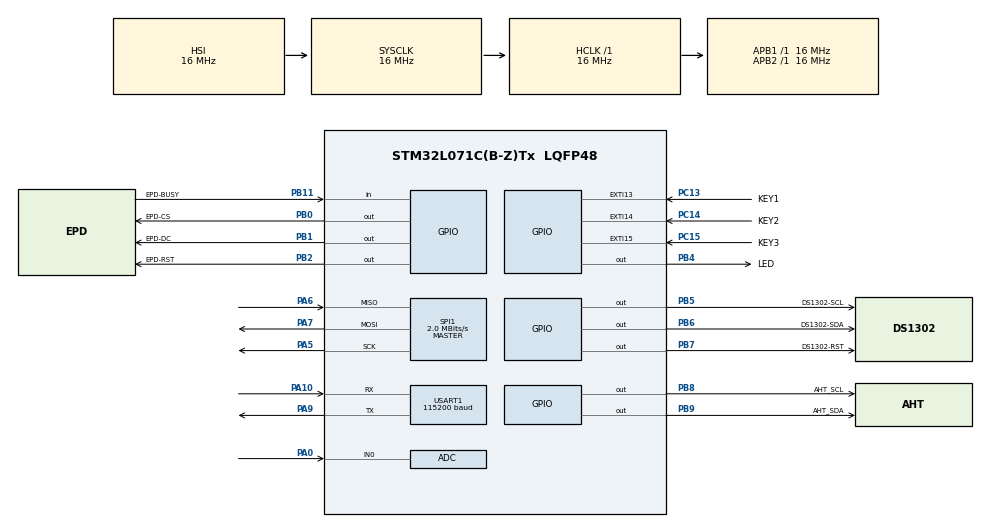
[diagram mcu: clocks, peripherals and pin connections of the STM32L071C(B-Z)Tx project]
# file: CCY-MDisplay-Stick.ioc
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ADC.ClockPrescaler=ADC_CLOCK_SYNC_PCLK_DIV1
ADC.ContinuousConvMode=DISABLE
ADC.DMAContinuousRequests=DISABLE
ADC.DataAlign=ADC_DATAALIGN_RIGHT
ADC.DiscontinuousConvMode=DISABLE
ADC.EOCSelection=ADC_EOC_SINGLE_CONV
ADC.EnableAnalogWatchDog=false
ADC.ExternalTrigConv=ADC_SOFTWARE_START
ADC.ExternalTrigConvEdge=ADC_EXTERNALTRIGCONVEDGE_NONE
ADC.LowPowerAutoPowerOff=DISABLE
ADC.LowPowerAutoWait=DISABLE
ADC.LowPowerFrequencyMode=DISABLE
ADC.NbrOfConversion=1
ADC.NbrOfConversionFlag=1
ADC.Overrun=ADC_OVR_DATA_PRESERVED
ADC.OversamplingMode=DISABLE
ADC.Rank-0\#ChannelRegularConversion=1
ADC.Resolution=ADC_RESOLUTION_12B
ADC.SamplingTime=ADC_SAMPLETIME_1CYCLE_5
ADC.ScanConvMode=ADC_SCAN_DIRECTION_FORWARD
ADC.master=1
Mcu.Family=STM32L0
Mcu.Name=STM32L071C(B-Z)Tx
Mcu.Package=LQFP48
NVIC.ADC1_COMP_IRQn=true\:0\:0\:false\:false\:true\:true\:true\:true
NVIC.EXTI4_15_IRQn=true\:0\:0\:false\:false\:true\:true\:true\:true
NVIC.RCC_IRQn=true\:0\:0\:false\:false\:true\:true\:false\:true
NVIC.USART1_IRQn=true\:0\:0\:false\:false\:true\:true\:true\:true
PA0.Mode=IN0
PA0.Signal=ADC_IN0
PA10.Mode=Asynchronous
PA10.Signal=USART1_RX
PA13.Mode=Serial_Wire
PA13.Signal=SYS_SWDIO
PA14.Mode=Serial_Wire
PA14.Signal=SYS_SWCLK
PA5.Mode=Full_Duplex_Master
PA5.Signal=SPI1_SCK
PA6.Mode=Full_Duplex_Master
PA6.Signal=SPI1_MISO
PA7.Mode=Full_Duplex_Master
PA7.Signal=SPI1_MOSI
PA9.Mode=Asynchronous
PA9.Signal=USART1_TX
PB0.GPIO_Label=EPD-CS
PB0.Signal=GPIO_Output
PB1.GPIO_Label=EPD-DC
PB1.Signal=GPIO_Output
PB11.GPIO_Label=EPD-BUSY
PB11.Signal=GPIO_Input
PB2.GPIO_Label=EPD-RST
PB2.Signal=GPIO_Output
PB4.GPIO_Label=LED
PB4.Signal=GPIO_Output
PB5.GPIO_Label=DS1302-SCL
PB5.Signal=GPIO_Output
PB6.GPIO_Label=DS1302-SDA
PB6.Signal=GPIO_Output
PB7.GPIO_Label=DS1302-RST
PB7.Signal=GPIO_Output
PB8.GPIO_Label=AHT_SCL
PB8.GPIO_ModeDefaultOutputPP=GPIO_MODE_OUTPUT_OD
PB8.GPIO_PuPd=GPIO_NOPULL
PB8.GPIO_Speed=GPIO_SPEED_FREQ_HIGH
PB8.Signal=GPIO_Output
PB9.GPIO_Label=AHT_SDA
PB9.GPIO_ModeDefaultOutputPP=GPIO_MODE_OUTPUT_OD
PB9.GPIO_PuPd=GPIO_NOPULL
PB9.GPIO_Speed=GPIO_SPEED_FREQ_HIGH
PB9.Signal=GPIO_Output
PC13.GPIO_Label=KEY1
PC13.GPIO_ModeDefaultEXTI=GPIO_MODE_IT_RISING_FALLING
PC13.Signal=GPXTI13
PC14-OSC32_IN.GPIO_Label=KEY2
PC14-OSC32_IN.GPIO_ModeDefaultEXTI=GPIO_MODE_IT_RISING_FALLING
PC14-OSC32_IN.Signal=GPXTI14
PC15-OSC32_OUT.GPIO_Label=KEY3
PC15-OSC32_OUT.GPIO_ModeDefaultEXTI=GPIO_MODE_IT_RISING_FALLING
PC15-OSC32_OUT.Signal=GPXTI15
PH0-OSC_IN.Mode=HSE-External-Oscillator
PH0-OSC_IN.Signal=RCC_OSC_IN
PH1-OSC_OUT.Mode=HSE-External-Oscillator
PH1-OSC_OUT.Signal=RCC_OSC_OUT
ProjectManager.HeapSize=0x200
ProjectManager.StackSize=0x400
ProjectManager.TargetToolchain=STM32CubeIDE
RCC.AHBFreq_Value=16000000
RCC.APB1Freq_Value=16000000
RCC.APB1TimFreq_Value=16000000
RCC.APB2Freq_Value=16000000
RCC.APB2TimFreq_Value=16000000
RCC.HCLKFreq_Value=16000000
RCC.HSE_VALUE=8000000
RCC.HSI16_VALUE=16000000
RCC.HSI_VALUE=16000000
RCC.LSE_VALUE=32768
RCC.MSI_VALUE=2097000
RCC.SYSCLKFreq_VALUE=16000000
RCC.SYSCLKSource=RCC_SYSCLKSOURCE_HSI
RCC.VCOOutputFreq_Value=48000000
RTC.AsynchPrediv=127
RTC.Date=1
RTC.DayLightSaving=RTC_DAYLIGHTSAVING_NONE
RTC.Format=RTC_FORMAT_BCD
RTC.HourFormat=RTC_HOURFORMAT_24
RTC.Hours=0
RTC.Minutes=0
RTC.Month=RTC_MONTH_JANUARY
RTC.Seconds=0
RTC.StoreOperation=RTC_STOREOPERATION_RESET
RTC.SynchPrediv=255
RTC.WeekDay=RTC_WEEKDAY_MONDAY
RTC.Year=0
SPI1.BaudRatePrescaler=SPI_BAUDRATEPRESCALER_8
SPI1.CLKPhase=SPI_PHASE_1EDGE
SPI1.CLKPolarity=SPI_POLARITY_LOW
SPI1.CRCCalculation=SPI_CRCCALCULATION_DISABLE
SPI1.CalculateBaudRate=2.0 MBits/s
SPI1.DataSize=SPI_DATASIZE_8BIT
SPI1.Direction=SPI_DIRECTION_2LINES
SPI1.FirstBit=SPI_FIRSTBIT_MSB
SPI1.Mode=SPI_MODE_MASTER
SPI1.NSS=SPI_NSS_SOFT
SPI1.TIMode=SPI_TIMODE_DISABLE
SPI1.VirtualType=VM_MASTER
TIM6.Prescaler=16-1
USART1.AutoBaudRateEnableParam=UART_ADVFEATURE_AUTOBAUDRATE_DISABLE
USART1.BaudRate=115200
USART1.DMADisableonRxErrorParam=ADVFEATURE_DMA_ENABLEONRXERROR
USART1.DataInvertParam=ADVFEATURE_DATAINV_DISABLE
USART1.MSBFirstParam=ADVFEATURE_MSBFIRST_DISABLE
USART1.Mode=MODE_TX_RX
USART1.OneBitSampling=UART_ONE_BIT_SAMPLE_DISABLE
USART1.OverSampling=UART_OVERSAMPLING_16
USART1.OverrunDisableParam=ADVFEATURE_OVERRUN_ENABLE
USART1.Parity=PARITY_NONE
USART1.RxPinLevelInvertParam=ADVFEATURE_RXINV_DISABLE
USART1.StopBits=STOPBITS_1
USART1.SwapParam=ADVFEATURE_SWAP_DISABLE
USART1.TxPinLevelInvertParam=ADVFEATURE_TXINV_DISABLE
USART1.VirtualMode-Asynchronous=VM_ASYNC
USART1.WordLength=WORDLENGTH_8B
VP_RTC_VS_RTC_Activate.Mode=RTC_Enabled
VP_RTC_VS_RTC_Calendar.Mode=RTC_Calendar
VP_TIM6_VS_ClockSourceINT.Mode=Enable_Timer
board=custom

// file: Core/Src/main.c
/* USER CODE BEGIN Header */
/**
  ******************************************************************************
  * @file           : main.c
  * @brief          : Main program body
  ******************************************************************************
  * @attention
  *
  * Copyright (c) 2023 STMicroelectronics.
  * All rights reserved.
  *
  * This software is licensed under terms that can be found in the LICENSE file
  * in the root directory of this software component.
  * If no LICENSE file comes with this software, it is provided AS-IS.
  *
  ******************************************************************************
  */
/* USER CODE END Header */
#include "main.h"
#include "adc.h"
#include "rtc.h"
#include "spi.h"
#include "tim.h"
#include "usart.h"
#include "gpio.h"

/* USER CODE BEGIN Includes */
#include "delay.h"
#include "display_logic.h"
/* USER CODE END Includes */

void SystemClock_Config(void);

int main(void)
{

  /* MCU Configuration--------------------------------------------------------*/

  /* Reset of all peripherals, Initializes the Flash interface and the Systick. */
  HAL_Init();

  /* Configure the system clock */
  SystemClock_Config();

  /* USER CODE BEGIN SysInit */
    delay_init(16);
  /* USER CODE END SysInit */

  /* Initialize all configured peripherals */
  MX_GPIO_Init();
  MX_RTC_Init();
  MX_USART1_UART_Init();
  MX_ADC_Init();
  MX_SPI1_Init();
  MX_TIM6_Init();

  /* Infinite loop */
  /* USER CODE BEGIN WHILE */
    logicInit();
    while (1) {
        logicRun();
    /* USER CODE END WHILE */

    }
}

void SystemClock_Config(void)
{
  RCC_OscInitTypeDef RCC_OscInitStruct = {0};
  RCC_ClkInitTypeDef RCC_ClkInitStruct = {0};
  RCC_PeriphCLKInitTypeDef PeriphClkInit = {0};

  /** Configure the main internal regulator output voltage
  */
  __HAL_PWR_VOLTAGESCALING_CONFIG(PWR_REGULATOR_VOLTAGE_SCALE1);

  /** Initializes the RCC Oscillators according to the specified parameters
  * in the RCC_OscInitTypeDef structure.
  */
  RCC_OscInitStruct.OscillatorType = RCC_OSCILLATORTYPE_HSI|RCC_OSCILLATORTYPE_LSI;
  RCC_OscInitStruct.HSIState = RCC_HSI_ON;
  RCC_OscInitStruct.HSICalibrationValue = RCC_HSICALIBRATION_DEFAULT;
  RCC_OscInitStruct.LSIState = RCC_LSI_ON;
  RCC_OscInitStruct.PLL.PLLState = RCC_PLL_NONE;
  if (HAL_RCC_OscConfig(&RCC_OscInitStruct) != HAL_OK)
  {
    Error_Handler();
  }

  /** Initializes the CPU, AHB and APB buses clocks
  */
  RCC_ClkInitStruct.ClockType = RCC_CLOCKTYPE_HCLK|RCC_CLOCKTYPE_SYSCLK
                              |RCC_CLOCKTYPE_PCLK1|RCC_CLOCKTYPE_PCLK2;
  RCC_ClkInitStruct.SYSCLKSource = RCC_SYSCLKSOURCE_HSI;
  RCC_ClkInitStruct.AHBCLKDivider = RCC_SYSCLK_DIV1;
  RCC_ClkInitStruct.APB1CLKDivider = RCC_HCLK_DIV1;
  RCC_ClkInitStruct.APB2CLKDivider = RCC_HCLK_DIV1;

  if (HAL_RCC_ClockConfig(&RCC_ClkInitStruct, FLASH_LATENCY_0) != HAL_OK)
  {
    Error_Handler();
  }
  PeriphClkInit.PeriphClockSelection = RCC_PERIPHCLK_USART1|RCC_PERIPHCLK_RTC;
  PeriphClkInit.Usart1ClockSelection = RCC_USART1CLKSOURCE_PCLK2;
  PeriphClkInit.RTCClockSelection = RCC_RTCCLKSOURCE_LSI;
  if (HAL_RCCEx_PeriphCLKConfig(&PeriphClkInit) != HAL_OK)
  {
    Error_Handler();
  }
}

void Error_Handler(void)
{
  /* USER CODE BEGIN Error_Handler_Debug */
    /* User can add his own implementation to report the HAL error return state */
    __disable_irq();
    while (1) {
        delay_ms(200);
        HAL_GPIO_TogglePin(LED_GPIO_Port, LED_Pin);
    }
  /* USER CODE END Error_Handler_Debug */
}
